# NANO112AN_v1 register map
File version: 1.0
Registers are 32-bit, read-write, reset 0x0 unless marked. A register's access mark holds for its fields unless they carry their own. Offsets are from the block's base; [hi:lo] are bit positions; {n}, {i} and the like mark numbered series; 'fields as' and 'values as' point back to an identical list.

## PWM — PWM Register Map
Base 0x40040000
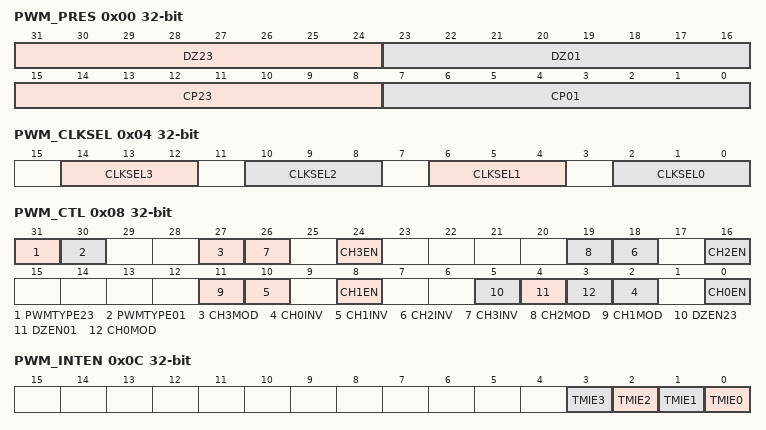
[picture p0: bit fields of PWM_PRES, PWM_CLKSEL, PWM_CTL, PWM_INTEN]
0x00 PWM_PRES — PWM Prescaler Register
  [31:24] DZ23 — Dead Zone Interval Register for CH2 and CH3 Pair. These 8 bits determine dead zone length. The unit time of dead zone length is received from clock selector 2.
  [23:16] DZ01 — Dead Zone Interval Register for CH0 and CH1 Pair. These 8 bits determine dead zone length. The unit time of dead zone length is received from clock selector 0.
  [15:8] CP23 — Clock Prescaler 2 for PWM Timer 2 3. Clock input is divided by (CP23 + 1) before it is fed to the PWM counter 2 3
  [7:0] CP01 — Clock Prescaler 0 for PWM Timer 0 1. Clock input is divided by (CP01 + 1) before it is fed to the PWM counter 0 1
0x04 PWM_CLKSEL — PWM Clock Select Register
  [14:12] CLKSEL3 — Timer 3 Clock Source Selection. Select clock input for timer 3.
    0=input clock is divided by 2; 1=input clock is divided by 4; 2=input clock is divided by 8; 3=input clock is divided by 16; 4=input clock is divided by 1
  [10:8] CLKSEL2 — Timer 2 Clock Source Selection. Select clock input for timer 2. (Table is the same as CLKSEL3)
  [6:4] CLKSEL1 — Timer 1 Clock Source Selection. Select clock input for timer 1. (Table is the same as CLKSEL3)
  [2:0] CLKSEL0 — Timer 0 Clock Source Selection. Select clock input for timer 0. (Table is the same as CLKSEL3)
0x08 PWM_CTL — PWM Control Register
  [31] PWMTYPE23 — Channel 2,3 Counter Mode
    0=Edge-aligned Mode; 1=Center-aligned Mode
  [30] PWMTYPE01 — Channel 0,1 Counter Mode
    0=Edge-aligned Mode; 1=Center-aligned Mode
  [27] CH3MOD — PWM-timer 3 Continuous/One-shot Mode. Note: If there is a rising transition at this bit, it will cause CN and CM of PWM0_DUTY3 to be cleared.
    0=One-Shot Mode; 1=Continuous Mode
  [8n+2] CH{n}INV (n=0..3) — PWM-timer {n} Output Inverter ON/OFF
    0=Inverter OFF; 1=Inverter ON
  [8n] CH{n}EN (n=0..3) — PWM-timer {n} Enable/Disable Start Run
    0=PWM-Timer {n} Running Stopped; 1=PWM-Timer {n} Start Run Enabled
  [19] CH2MOD — PWM-timer 2 Continuous/One-shot Mode. Note: If there is a rising transition at this bit, it will cause CN and CM of PWM0_DUTY2 be cleared.
    0=One-Shot Mode; 1=Continuous Mode
  [11] CH1MOD — PWM-timer 1 Continuous/One-shot Mode. Note: If there is a rising transition at this bit, it will cause CN and CM of PWM0_DUTY1 to be cleared.
    0=One-Shot Mode; 1=Continuous Mode
  [5] DZEN23 — Dead-zone 2 Generator Enable/Disable Control. Note: When Dead-Zone Generator is enabled, the pair of PWM2 and PWM3 becomes a complementary pair.
    0=Disabled; 1=Enabled
  [4] DZEN01 — Dead-zone 0 Generator Enable/Disable Control. Note: When Dead-Zone Generator is enabled, the pair of PWM0 and PWM1 becomes a complementary pair.
    0=Disabled; 1=Enabled
  [3] CH0MOD — PWM-timer 0 Continuous/One-shot Mode. Note: If there is a rising transition at this bit, it will cause CN and CM of PWM0_DUTY0 to be cleared.
    0=One-Shot Mode; 1=Continuous Mode
0x0C PWM_INTEN — PWM Interrupt Enable Register
  [all] fields
    0=Disabled; 1=Enabled
  [n] TMIE{n} (n=0..3) — PWM Timer {n} Interrupt Enable Control
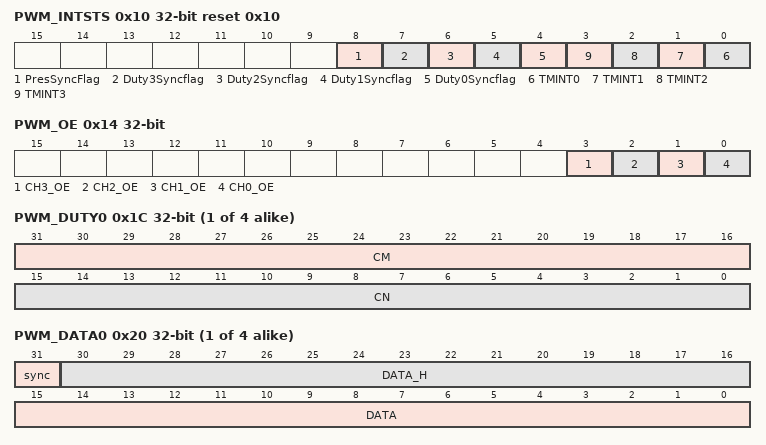
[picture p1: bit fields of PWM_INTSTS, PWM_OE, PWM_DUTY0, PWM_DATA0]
0x10 PWM_INTSTS reset 0x10 — PWM Interrupt Indication Register
  [8] PresSyncFlag — Prescale Synchronize Flag. Note: software should check this flag when writing Prescale, if this flag is set, and user ignore this flag and change Prescale, the Prescale may be wrong for one prescale cycle
    0=Two Prescales have been synchronized to corresponding PWM_CLK (of channel 0,1 or channel 2, 3) domain respectively; 1=Prescale01 is synchronizing to PWM_CLK domain of channel 0,1 or Prescaler23 is synchronizing to PWM_CLK domain of channel 2, 3
  [7] Duty3Syncflag — Duty3 Synchronize Flag. Note: software should check this flag when writing duty3, if this flag is set, and user ignore this flag and change duty3, the corresponding CNR and CMR may be wrong for one duty cycle
    0=Duty3 has been synchronized to PWM_CLK domain of channel 2, 3; 1=Duty3 is synchronizing to PWM_CLK domain of channel 2, 3
  [6] Duty2Syncflag — Duty2 Synchronize Flag. Note: software should check this flag when writing duty2, if this flag is set, and user ignore this flag and change duty2, the corresponding CNR and CMR may be wrong for one duty cycle
    0=Duty2 has been synchronized to PWM_CLK domain of channel 2, 3; 1=Duty2 is synchronizing to PWM_CLK domain of channel 2, 3
  [5] Duty1Syncflag — Duty1 Synchronize Flag. Note: software should check this flag when writing duty1, if this flag is set, and user ignore this flag and change duty1, the corresponding CNR and CMR may be wrong for one duty cycle
    0=Duty1 has been synchronized to PWM_CLK domain of channel 0, 1; 1=Duty1 is synchronizing to PWM_CLK domain of channel 0, 1
  [4] Duty0Syncflag — Duty0 Synchronize Flag. Note: software should check this flag when writing duty0, if this flag is set, and user ignore this flag and change duty0, the corresponding CNR and CMR may be wrong for one duty cycle
    0=Duty0 has been synchronized to PWM_CLK domain of channel 0, 1; 1=Duty0 is synchronizing to PWM_CLK domain of channel 0, 1
  [n] TMINT{n} (n=0..3) — PWM Timer {n} Interrupt Flag. Flag is set by hardware when PWM{n} down counter reaches 0, software can clear this bit by writing a one to it.
0x14 PWM_OE — PWM Output Enable for PWM0~PWM3
  [3] CH3_OE — PWM CH3 Output Enable Control. Note: The corresponding GPI/O pin also must be switched to PWM function. (refer to PCx_MFP / PDx_MFP / Pex_MFP / PFx_MFP)
    0=PWM CH3 output to pin Disabled; 1=PWM CH3 output to pin Enabled
  [2] CH2_OE — PWM CH2 Output Enable Control R. Note: The corresponding GPI/O pin also must be switched to PWM function. (refer to PCx_MFP / PDx_MFP / Pex_MFP / PFx_MFP)
    0=PWM CH2 output to pin Disabled; 1=PWM CH2 output to pin Enabled
  [1] CH1_OE — PWM CH1 Output Enable Control. Note: The corresponding GPI/O pin also must be switched to PWM function. (refer to PBx_MFP / PCx_MFP / PDx_MFP)
    0=PWM CH1 output to pin Disabled; 1=PWM CH1 output to pin Enabled
  [0] CH0_OE — PWM CH0 Output Enable Control. Note: The corresponding GPI/O pin also must be switched to PWM function (refer to PBx_MFP / PCx_MFP / PDx_MFP)
    0=PWM CH0 output to pin Disabled; 1=PWM CH0 output to pin Enabled
{0x1C+0xC*i} PWM_DUTY{i} (i=0..3) — PWM Counter/Comparator Register {i}
  [31:16] CM — PWM Comparator Register. CM determines the PWM duty. In edge-aligned mode, Note:Any write to CM will take effect in next PWM cycle.
  [15:0] CN — PWM Counter/Timer Loaded Value. CN determines the PWM period. In edge-aligned mode, Note: Any write to CN will take effect in next PWM cycle.
{0x20+0xC*i} PWM_DATA{i} ro (i=0..3) — PWM Data Register {i}
  [31] sync — CN Value Sync with PWM Counter. Note: when the corresponding cascade enable bit is set, this bit will not appear in the corresponding channel
    0=CN value is sync to PWM counter; 1=CN value is not sync to PWM counter
  [30:16] DATA_H — PWM Data Register. User can monitor PWM_DATA to know the current value in 32-bit down count counter of corresponding channel. Notes: This will be valid only for the corresponding cascade enable bit is set
  [15:0] DATA — PWM Data Register. User can monitor PWM_DATA to know the current value in 16-bit down count counter of corresponding channel.
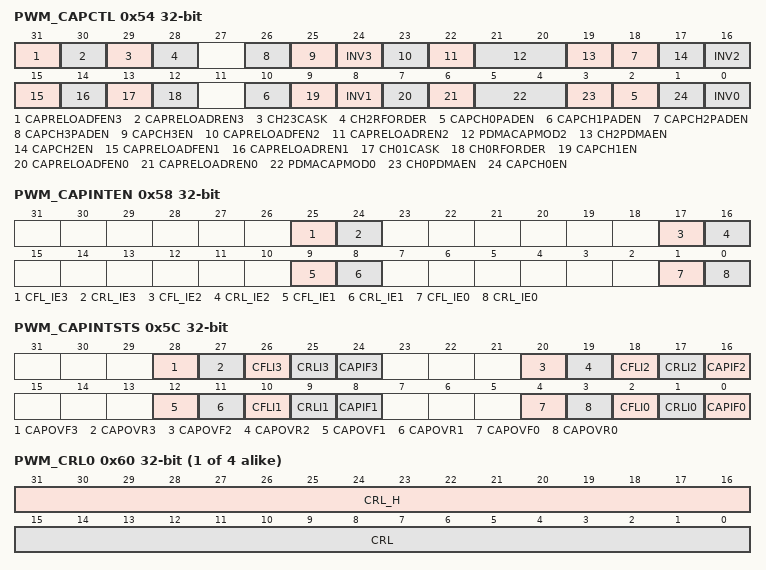
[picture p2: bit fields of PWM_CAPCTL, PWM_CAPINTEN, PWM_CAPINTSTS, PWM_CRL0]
0x54 PWM_CAPCTL — Capture Control Register
  [31] CAPRELOADFEN3 — Reload CNR3 When CH3 Falling Capture Event Comes
    0=Falling capture reload for CH3 Disabled; 1=Falling capture reload for CH3 Enabled
  [30] CAPRELOADREN3 — Reload CNR3 When CH3 Rising Capture Event Comes
    0=Rising capture reload for CH3 Disabled; 1=Rising capture reload for CH3 Enabled
  [29] CH23CASK — Cascade channel 2 and channel 3 PWM counter for capturing usage
  [28] CH2RFORDER
    0=PWM_CFL2 is the first captured data to memory; 1=PWM_CRL2 is the first captured data to memory
  [8n+2] CAPCH{n}PADEN (n=0..3) — Capture Input Enable Control
    0=Disable the channel {n} input capture signal from corresponding multi-function pin; 1=Enable the channel {n} input capture signal from corresponding multi-function pin
  [25] CAPCH3EN — Capture Channel 3 Transition Enable/Disable Control. When Enabled, Capture latched the PMW-timer and saved to CRL3 (PWM_CRL3[15:0]) for rising latch and CFL3 (PWM_CFL3[15:0]) for falling latch. When Disabled, Capture does not update CRL3 (PWM_CRL3[15:0]) and CFL3 (PWM_CFL3[15:0]), and disable Channel 3 Interrupt.
    0=Capture function on channel 3 Disabled; 1=Capture function on channel 3 Enabled
  [8n] INV{n} (n=0..3) — Channel {n} Inverter ON/OFF
    0=Inverter OFF; 1=Inverter ON. Reverse the input signal from GPIO before fed to Capture timer
  [23] CAPRELOADFEN2 — Reload CNR2 When CH2 Capture Failing Event Coming
    0=Failing capture reload for CH2 Disabled; 1=Failing capture reload for CH2 Enabled
  [22] CAPRELOADREN2 — Reload CNR2 When CH2 Capture Rising Event Coming
    0=Rising capture reload for CH2 Disabled; 1=Rising capture reload for CH2 Enabled
  [21:20] PDMACAPMOD2 — Select CRL2 or CFL2 for PDMA Transfer
    1=CRL2 will be transmitted; 2=CFL2 will be transmitted; 3=Both CRL2 and CFL2 will be transmitted
  [19] CH2PDMAEN — Channel 2 PDMA Enable Control
    0=Channel 2 PDMA function Disabled; 1=Channel 2 PDMA function Enabled for the channel 2 captured data and transfer to memory
  [17] CAPCH2EN — Capture Channel 2 Transition Enable/Disable Control. When Enabled, Capture latched the PWM-timer value and saved to CRL2 (PWM_CRL2[15:0]) for rising latch and CFL2 (PWM_CFL2[15:0]) for falling latch. When Disabled, Capture does not update CRL2 (PWM_CRL2[15:0]) and CFL2 (PWM_CFL2[15:0]), and disable Channel 2 Interrupt.
    0=Capture function on channel 2 Disabled; 1=Capture function on channel 2 Enabled
  [15] CAPRELOADFEN1 — Reload CNR1 When CH1 Capture Falling Event Coming
    0=Capture falling reload for CH1 Disabled; 1=Capture falling reload for CH1 Enabled
  [14] CAPRELOADREN1 — Reload CNR1 When CH1 Capture Rising Event Comes
    0=Rising capture reload for CH1 Disabled; 1=Rising capture reload for CH1 Enabled
  [13] CH01CASK — Cascade channel 0 and channel 1 PWM timer for capturing usage
  [12] CH0RFORDER
    0=PWM_CFL0 is the first captured data to memory; 1=PWM_CRL0 is the first captured data to memory
  [9] CAPCH1EN — Capture Channel 1 Transition Enable/Disable Control. When Enabled, Capture latched the PMW-counter and saved to CRL1 (PWM_CRL1[15:0]) for rising latch and CFL1 (PWM_CFL1[15:0]) for falling latch. When Disabled, Capture does not update CRL1 (PWM_CRL1[15:0]) and CFL1 (PWM_CFL1[15:0]), and disable Channel 1 Interrupt.
    0=Capture function on channel 1 Disabled; 1=Capture function on channel 1 Enabled
  [7] CAPRELOADFEN0 — Reload CNR0 When CH0 Capture Falling Event Comes
    0=Falling capture reload for CH0 Disabled; 1=Falling capture reload for CH0 Enabled
  [6] CAPRELOADREN0 — Reload CNR0 When CH0 Capture Rising Event Comes
    0=Rising capture reload for CH0 Disabled; 1=Rising capture reload for CH0 Enabled
  [5:4] PDMACAPMOD0 — Select CRL0 or CFL0 for PDMA Transfer
    1=CRL0 will be transmitted; 2=CFL0 will be transmitted; 3=Both CRL0 and CFL0 will be transmitted
  [3] CH0PDMAEN — Channel 0 PDMA Enable Control
    0=Channel 0 PDMA function Disabled; 1=Channel 0 PDMA function Enabled for the channel 0 captured data and transfer to memory
  [1] CAPCH0EN — Capture Channel 0 Transition Enable/Disable Control. When Enabled, Capture latched the PWM-timer value and saved to CRL0 (PWM_CRL0[15:0]) for rising latch and CFL0 (PWM_CFL0[15:0]) for falling latch. When Disabled, Capture does not update CRL0 (PWM_CRL0[15:0]) and CFL0 (PWM_CFL0[15:0]), and disable Channel 0 Interrupt.
    0=Capture function on channel 0 Disabled; 1=Capture function on channel 0 Enabled
0x58 PWM_CAPINTEN — Capture Interrupt Enable Register
  [25] CFL_IE3 — Channel 3 Falling Latch Interrupt Enable ON/OFF. When Enabled, if Capture detects Channel 3 has falling transition, Capture issues an Interrupt.
    0=Falling latch interrupt Disabled; 1=Falling latch interrupt Enabled
  [24] CRL_IE3 — Channel 3 Rising Latch Interrupt Enable ON/OFF. When Enabled, if Capture detects Channel 3 has rising transition, Capture issues an Interrupt.
    0=Rising latch interrupt Disabled; 1=Rising latch interrupt Enabled
  [17] CFL_IE2 — Channel 2 Falling Latch Interrupt Enable ON/OFF. When Enabled, if Capture detects Channel 2 has falling transition, Capture issues an Interrupt.
    values as CFL_IE3
  [16] CRL_IE2 — Channel 2 Rising Latch Interrupt Enable ON/OFF. When Enabled, if Capture detects Channel 2 has rising transition, Capture issues an Interrupt.
    values as CRL_IE3
  [9] CFL_IE1 — Channel 1 Falling Latch Interrupt Enable Control. When Enabled, if Capture detects Channel 1 has falling transition, Capture issues an Interrupt.
    values as CFL_IE3
  [8] CRL_IE1 — Channel 1 Rising Latch Interrupt Enable Control. When Enabled, if Capture detects Channel 1 has rising transition, Capture issues an Interrupt.
    values as CRL_IE3
  [1] CFL_IE0 — Channel 0 Falling Latch Interrupt Enable ON/OFF. When Enabled, if Capture detects Channel 0 has falling transition, Capture issues an Interrupt.
    values as CFL_IE3
  [0] CRL_IE0 — Channel 0 Rising Latch Interrupt Enable ON/OFF. When Enabled, if Capture detects Channel 0 has rising transition, Capture issues an Interrupt.
    values as CRL_IE3
0x5C PWM_CAPINTSTS — Capture Interrupt Indication Register
  [28] CAPOVF3 — Capture Falling Flag Over Run for Channel 3. This flag indicate CFL3 update faster than software reading it when it is set. This bit will be cleared automatically when user clear CFLI3 (PWM_CAPINTSTS[26])
  [27] CAPOVR3 — Capture Rising Flag Over Run for Channel 3. This flag indicate CRL3update faster than software reading it when it is set. This bit will be cleared automatically when user clear CRLI3 (PWM_CAPINTSTS[25])
  [26] CFLI3 — PWM_CFL3 Latched Indicator Bit. When input channel 3 has a falling transition, PWM_CFL3 was latched with the value of PWM down-counter and this bit is set by hardware, software can clear this bit by writing 1 to it.
  [25] CRLI3 — PWM_CRL3 Latched Indicator Bit. When input channel 3 has a rising transition, PWM_CRL3 was latched with the value of PWM down-counter and this bit is set by hardware, software can clear this bit by writing 1 to it.
  [8n] CAPIF{n} (n=0..3) — Capture{n} Interrupt Indication Flag. If channel {n} rising latch interrupt (CRL_IE{n}, PWM_CAPINTEN[{8n}]) is enabled, a rising transition occurs at input channel {n} will result in CAPIF{n} to high; Similarly, a falling transition will cause CAPIF{n} to be set high if channel {n} falling latch interrupt (CFL_IE{n}, PWM_CAPINTEN[{8n+1}]) is enabled. This flag is cleared by software with a write 1 on it.
  [20] CAPOVF2 — Capture Falling Flag Over Run for Channel 2. This flag indicate CFL2 update faster than software reading it when it is set. This bit will be cleared automatically when user clear CFLI2 (PWM_CAPINTSTS[18])
  [19] CAPOVR2 — Capture Rising Flag Over Run for Channel 2. This flag indicate CRL2 update faster than software reading it when it is set. This bit will be cleared automatically when user clear CRLI2 (PWM_CAPINTSTS[17])
  [18] CFLI2 — PWM_CFL2 Latched Indicator Bit. When input channel 2 has a falling transition, PWM0_CFL2 was latched with the value of PWM down-counter and this bit is set by hardware, software can clear this bit by writing 1 to it.
  [17] CRLI2 — PWM_CRL2 Latched Indicator Bit. When input channel 2 has a rising transition, PWM0_CRL2 was latched with the value of PWM down-counter and this bit is set by hardware, software can clear this bit by writing 1 to it.
  [12] CAPOVF1 — Capture Falling Flag Over Run for Channel 1. This flag indicate CFL1 update faster than software reading it when it is set. This bit will be cleared automatically when user clear CFLI1 (PWM_CAPINTSTS[10])
  [11] CAPOVR1 — Capture Rising Flag Over Run for Channel 1. This flag indicate CRL1 update faster than software reading it when it is set. This bit will be cleared automatically when user clear CRLI1 (PWM_CAPINTSTS[9])
  [10] CFLI1 — PWM_CFL1 Latched Indicator Bit. When input channel 1 has a falling transition, PWM_CFL1 was latched with the value of PWM down-counter and this bit is set by hardware, software can clear this bit by writing 1 to it.
  [9] CRLI1 — PWM_CRL1 Latched Indicator Bit. When input channel 1 has a rising transition, PWM_CRL1 was latched with the value of PWM down-counter and this bit is set by hardware, software can clear this bit by writing 1 to it.
  [4] CAPOVF0 — Capture Falling Flag Over Run for Channel 0. This flag indicate CFL0 update faster than software read it when it is set. This bit will be cleared automatically when user clear CFLI0 (PWM_CAPINTSTS[2])
  [3] CAPOVR0 — Capture Rising Flag Over Run for Channel 0. This flag indicate CRL0 update faster than software reading it when it is set. This bit will be cleared automatically when user clears CRLI0 (PWM_CAPINTSTS[1]).
  [2] CFLI0 — PWM_CFL0 Latched Indicator Bit. When input channel 0 has a falling transition, PWM0_CFL0 was latched with the value of PWM down-counter and this bit is set by hardware, software can clear this bit by writing 1 to it.
  [1] CRLI0 — PWM_CRL0 Latched Indicator Bit. When input channel 0 has a rising transition, PWM0_CRL0 was latched with the value of PWM down-counter and this bit is set by hardware, software can clear this bit by writing 1 to it.
{0x60+8i} PWM_CRL{i} ro (i=0..3) — Capture Rising Latch Register (Channel {i})
  [31:16] CRL_H — Upper Half Word of 32-bit Capture Data When Cascade Enable Control. When cascade is enabled for capture channel 0, 2,the original 16 bit counter extend to 32 bit, and capture result CRL0 and CRL2 are also extend to 32 bit,
  [15:0] CRL — Capture Rising Latch Register. Latch the PWM counter when Channel 0/1/2/3 has rising transition.
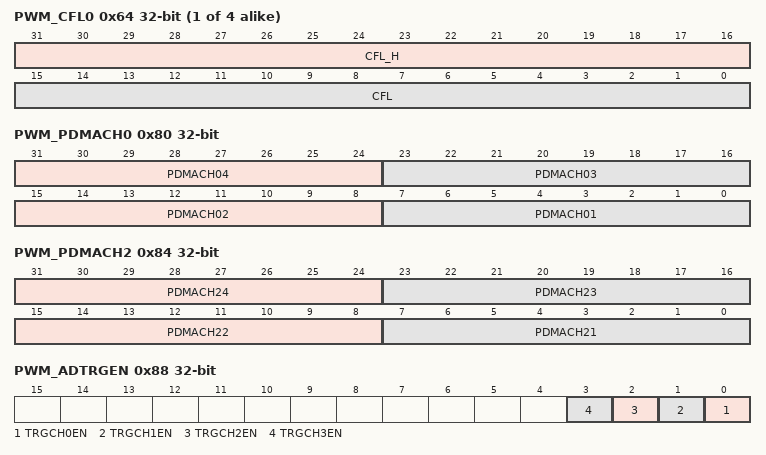
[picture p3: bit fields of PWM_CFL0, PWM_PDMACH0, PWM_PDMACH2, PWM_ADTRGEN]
{0x64+8i} PWM_CFL{i} ro (i=0..3) — Capture Falling Latch Register (Channel {i})
  [31:16] CFL_H — Upper Half Word of 32-bit Capture Data When Cascade Enable Control. When cascade is enabled for capture channel 0, 2, the original 16 bit counter will be extended to 32 bit, and capture result CFL0 and CFL2 are also extended to 32 bit,
  [15:0] CFL — Capture Falling Latch Register. Latch the PWM counter when Channel 0/1/2/3 has Falling transition.
0x80 PWM_PDMACH0 ro — PDMA Channel 0 Captured Data
  [31:24] PDMACH04 — Captured Data of Channel 0. When CH01CASK is disabled, this byte is 0. When CH01CASK is enabled, It is the 4th byte of 32 bit capturing data for channel 0. Note: This register is used as a buffer to transfer PWM captured rising or falling data to memory by PDMA.
  [23:16] PDMACH03 — Captured Data of Channel 0. When CH01CASK is disabled, this byte is 0. When CH01CASK is enabled, It is the 3rd byte of 32 bit capturing data for channel 0. Note: This register is used as a buffer to transfer PWM captured rising or falling data to memory by PDMA.
  [15:8] PDMACH02 — Captured Data of Channel 0. When CH01CASK is disabled, this byte is 0. When CH01CASK is enabled, It is the 2nd byte of 32 bit capturing data for channel 0. Note: This register is used as a buffer to transfer PWM captured rising or falling data to memory by PDMA.
  [7:0] PDMACH01 — Captured Data of Channel 0. When CH01CASK is disabled, this byte is 0. When CH01CASK is enabled, It is the 1st byte of 32 bit capturing data for channel 0. Note: This register is used as a buffer to transfer PWM captured rising or falling data to memory by PDMA.
0x84 PWM_PDMACH2 ro — PDMA Channel 2 Captured Data
  [31:24] PDMACH24 — Captured Data of Channel 2. When CH23CASK is disabled, this byte is 0. When CH23CASK is enabled, It is the 4th byte of 32 bit capturing data for channel 0. Note: This register is used as a buffer to transfer PWM captured rising or falling data to memory by PDMA.
  [23:16] PDMACH23 — Captured Data of Channel 2. When CH23CASK is disabled, this byte is 0. When CH23CASK is enabled, It is the 3rd byte of 32 bit capturing data for channel 0. Note: This register is used as a buffer to transfer PWM captured rising or falling data to memory by PDMA.
  [15:8] PDMACH22 — Captured Data of Channel 2. When CH23CASK is disabled, this byte is 0. When CH23CASK is enabled, It is the 2nd byte of 32 bit capturing data for channel 0. Note: This register is used as a buffer to transfer PWM captured rising or falling data to memory by PDMA.
  [7:0] PDMACH21 — Captured Data of Channel 2. When CH23CASK is disabled, this byte is 0. When CH23CASK is enabled, It is the 1st byte of 32 bit capturing data for channel 0. Note: This register is used as a buffer to transfer PWM captured rising or falling data to memory by PDMA.
0x88 PWM_ADTRGEN — PWM Center-triggered Control Register
  [n] TRGCH{n}EN (n=0..3) — PWM CH{n} Center-triggered Enable Control. Note: The center-triggered function is only valid in PWM center-aligned mode.
    0=PWM CH{n} center-triggered function Disabled; 1=PWM CH{n} center-triggered function Enabled
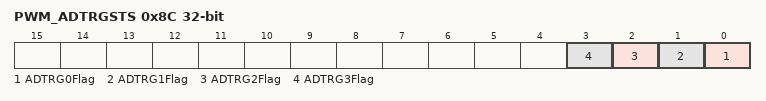
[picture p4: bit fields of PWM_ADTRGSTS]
0x8C PWM_ADTRGSTS ro — PWM Center-triggered Indication Register
  [n] ADTRG{n}Flag (n=0..3) — PWM CH{n} Center-triggered Flag. Note: This flag is only valid in center-aligned mode, and software could write 1 into this bit to clear the flag
    0=PWM CH{n} has not crossed half of PWM period yet; 1=PWM CH{n} has crossed half of PWM period
